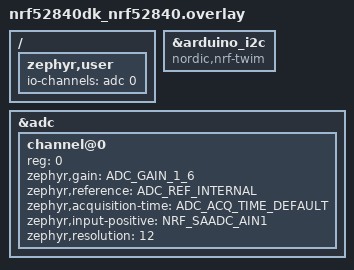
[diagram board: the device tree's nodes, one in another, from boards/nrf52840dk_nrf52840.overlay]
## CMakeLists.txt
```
cmake_minimum_required(VERSION 3.20.0)

find_package(Zephyr REQUIRED HINTS $ENV{ZEPHYR_BASE})
project(ble_sensor_logger)

target_sources(app PRIVATE
  src/main.c
  src/protocol/protocol.c
  src/modules/ble_service.c
  src/modules/control.c
  src/modules/hts221_sensor.c
  src/modules/lps22hb_sensor.c
  src/modules/lsm303agr_magn_sensor.c
  src/modules/lsm6dsl_sensor.c
  src/modules/sensor_dummy.c
  src/platform/platform_time.c
  src/events/ble_events.c
  src/events/config_events.c
  src/events/sensor_events.c
  src/events/status_events.c
)

target_sources_ifdef(CONFIG_BSL_IKS01A2_I2C_PROBE app PRIVATE
  src/modules/iks01a2_i2c_probe.c
)

target_include_directories(app PRIVATE
  src
  src/events
  src/modules
  src/platform
  src/protocol
)

target_link_libraries(app PRIVATE m)
```

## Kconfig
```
source "Kconfig.zephyr"

menu "BLE Sensor Logger"

config BSL_IKS01A2_I2C_PROBE
	bool "Enable X-NUCLEO-IKS01A2 I2C probe logging"
	depends on I2C && SENSOR
	default n
	help
	  Enable boot-time sensor API checks and periodic raw WHO_AM_I reads on
	  the X-NUCLEO-IKS01A2 Arduino I2C bus. This is intended for bring-up,
	  logic analyzer, and RTT/VCOM diagnostics, not for normal streaming
	  firmware.

config BSL_ORIENTATION_FRONT_AXIS
	string "Device front axis for LSM6DSL orientation stream"
	default "+X"
	help
	  Select the LSM6DSL raw accelerometer axis that points toward the
	  device front direction. Valid values are +X, -X, +Y, -Y, +Z, and -Z.

config BSL_ORIENTATION_GRAVITY_AXIS
	string "Device gravity axis for LSM6DSL orientation stream"
	default "+Z"
	help
	  Select the LSM6DSL raw accelerometer axis that matches the gravity
	  direction in the reference posture. Valid values are +X, -X, +Y, -Y,
	  +Z, and -Z. This must not use the same physical axis as the front
	  axis.

config BSL_GYRO_CALIB_THRESHOLD_MDPS
	int "Gyro auto-calibration still threshold in mdps"
	default 50
	range 10 1000
	help
	  Per-axis threshold in milli-degrees-per-second. The auto-calibration
	  considers the device still when all three calibrated gyro axes stay
	  within this threshold for the configured window of consecutive samples.

config BSL_GYRO_CALIB_ALPHA_PERMILLE
	int "Gyro auto-calibration bias lerp rate in permille"
	default 5
	range 0 1000
	help
	  IIR coefficient for gradually applying the bias offset, expressed as
	  permille (0-1000 maps to 0.000-1.000). A lower value makes corrections
	  smoother and slower. Default 5 (0.005 per sample at 26 Hz).

config BSL_GYRO_CALIB_WINDOW_SAMPLES
	int "Gyro auto-calibration consecutive still samples required"
	default 26
	range 5 260
	help
	  Number of consecutive samples the device must remain still before the
	  bias update is applied. At 26 Hz the default of 26 corresponds to
	  approximately 1 second.

config BSL_LATENCY_PRIORITY
	bool "Prefer latency over throughput for Sensor Data"
	default n
	help
	  Disable Sensor Data batching and always emit one sample per frame
	  (sample_count=1) for all streams while keeping protocol version v4.

endmenu
```

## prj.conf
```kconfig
CONFIG_BT=y
CONFIG_BT_PERIPHERAL=y
CONFIG_BT_DEVICE_NAME="BLE_SENSOR_LOGGER"
CONFIG_BT_DEVICE_APPEARANCE=0
CONFIG_BT_MAX_CONN=1
CONFIG_BT_GATT_CLIENT=n
CONFIG_BT_L2CAP_TX_MTU=247
CONFIG_BT_BUF_ACL_TX_SIZE=251
CONFIG_BT_BUF_ACL_RX_SIZE=251
CONFIG_I2C=y
CONFIG_SENSOR=y

CONFIG_APP_EVENT_MANAGER=y
CONFIG_APP_EVENT_MANAGER_LOG_EVENT_TYPE=n

CONFIG_MAIN_STACK_SIZE=2048
CONFIG_SYSTEM_WORKQUEUE_STACK_SIZE=2048
CONFIG_HEAP_MEM_POOL_SIZE=2048

CONFIG_LOG=y
CONFIG_LOG_DEFAULT_LEVEL=3
CONFIG_ASSERT=y

# Sensor driver debug logging
CONFIG_SENSOR_LOG_LEVEL_DBG=y
CONFIG_I2C_LOG_LEVEL_DBG=y
```

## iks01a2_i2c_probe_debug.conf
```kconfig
# Enable X-NUCLEO-IKS01A2 bring-up probe logging.
CONFIG_BSL_IKS01A2_I2C_PROBE=y

# Enable LSM303AGR driver paths exposed by the X-NUCLEO-IKS01A2 shield.
CONFIG_LIS2MDL=y
CONFIG_LIS2MDL_TRIGGER_NONE=y
CONFIG_LIS2DH=y
CONFIG_LIS2DH_TRIGGER_NONE=y
```

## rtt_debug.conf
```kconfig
# RTT-only debug logging for prototype boards without VCOM.
CONFIG_USE_SEGGER_RTT=y
CONFIG_CONSOLE=n
CONFIG_UART_CONSOLE=n
CONFIG_LOG_BACKEND_RTT=y
CONFIG_LOG_BACKEND_RTT_MODE_DROP=y
CONFIG_LOG_BACKEND_UART=n
```

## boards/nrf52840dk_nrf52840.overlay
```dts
#include <zephyr/dt-bindings/adc/nrf-saadc.h>

/ {
	zephyr,user {
		io-channels = <&adc 0>;
	};
};

&arduino_i2c {
	compatible = "nordic,nrf-twim";
};

&adc {
	#address-cells = <1>;
	#size-cells = <0>;

	channel@0 {
		reg = <0>;
		zephyr,gain = "ADC_GAIN_1_6";
		zephyr,reference = "ADC_REF_INTERNAL";
		zephyr,acquisition-time = <ADC_ACQ_TIME_DEFAULT>;
		zephyr,input-positive = <NRF_SAADC_AIN1>; /* P0.03, DK header A0 */
		zephyr,resolution = <12>;
	};
};
```

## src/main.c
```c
#include <app_event_manager.h>
#include <zephyr/kernel.h>
#include <zephyr/logging/log.h>

#include "ble_service.h"
#include "control.h"
#include "hts221_sensor.h"
#if IS_ENABLED(CONFIG_BSL_IKS01A2_I2C_PROBE)
#include "iks01a2_i2c_probe.h"
#endif
#include "lps22hb_sensor.h"
#include "lsm303agr_magn_sensor.h"
#include "lsm6dsl_sensor.h"
#include "sensor_dummy.h"

LOG_MODULE_REGISTER(main, LOG_LEVEL_INF);

int main(void)
{
	int err;

	LOG_INF("BLE Sensor Logger starting");

	err = app_event_manager_init();
	if (err) {
		LOG_ERR("app_event_manager_init failed: %d", err);
		return err;
	}

	err = sensor_dummy_init();
	if (err) {
		LOG_ERR("sensor_dummy_init failed: %d", err);
		return err;
	}

#if IS_ENABLED(CONFIG_BSL_IKS01A2_I2C_PROBE)
	iks01a2_i2c_probe_run();
#endif

	err = lsm6dsl_sensor_init();
	if (err) {
		LOG_ERR("lsm6dsl_sensor_init failed: %d", err);
	}

	err = hts221_sensor_init();
	if (err) {
		LOG_ERR("hts221_sensor_init failed: %d", err);
	}

	err = lps22hb_sensor_init();
	if (err) {
		LOG_ERR("lps22hb_sensor_init failed: %d", err);
	}

	err = lsm303agr_magn_sensor_init();
	if (err) {
		LOG_ERR("lsm303agr_magn_sensor_init failed: %d", err);
	}

	err = control_init();
	if (err) {
		LOG_ERR("control_init failed: %d", err);
		return err;
	}

	err = ble_service_init();
	if (err) {
		LOG_ERR("ble_service_init failed: %d", err);
		return err;
	}

	LOG_INF("BLE Sensor Logger ready");
	return 0;
}
```
